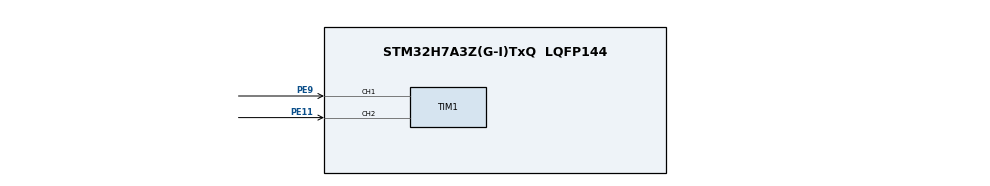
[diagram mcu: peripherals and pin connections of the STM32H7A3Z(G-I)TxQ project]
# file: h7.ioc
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Mcu.Family=STM32H7
Mcu.Name=STM32H7A3Z(G-I)TxQ
Mcu.Package=LQFP144
NVIC.PriorityGroup=NVIC_PRIORITYGROUP_4
PE11.Signal=S_TIM1_CH2
PE9.Signal=S_TIM1_CH1
PH0-OSC_IN.Mode=HSE-External-Oscillator
PH0-OSC_IN.Signal=RCC_OSC_IN
PH1-OSC_OUT.Mode=HSE-External-Oscillator
PH1-OSC_OUT.Signal=RCC_OSC_OUT
ProjectManager.HeapSize=0x200
ProjectManager.StackSize=0x400
ProjectManager.TargetToolchain=STM32CubeIDE
RCC.ADCFreq_Value=129000000
RCC.APB1Freq_Value=32000000
RCC.APB2Freq_Value=32000000
RCC.APB3Freq_Value=32000000
RCC.APB4Freq_Value=32000000
RCC.CDPPRE=RCC_APB3_DIV2
RCC.CDPPRE1=RCC_APB1_DIV2
RCC.CDPPRE2=RCC_APB2_DIV2
RCC.CortexFreq_Value=64000000
RCC.HCLKFreq_Value=64000000
RCC.SRDPPRE=RCC_APB4_DIV2
RCC.SYSCLKFreq_VALUE=64000000
RCC.USBFreq_Value=129000000
SH.S_TIM1_CH1.0=TIM1_CH1,Encoder_Interface
SH.S_TIM1_CH2.0=TIM1_CH2,Encoder_Interface
TIM1.EncoderMode=TIM_ENCODERMODE_TI12
board=custom

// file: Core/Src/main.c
/* USER CODE BEGIN Header */
/**
  ******************************************************************************
  * @file           : main.c
  * @brief          : Main program body
  ******************************************************************************
  * @attention
  *
  * Copyright (c) 2023 STMicroelectronics.
  * All rights reserved.
  *
  * This software is licensed under terms that can be found in the LICENSE file
  * in the root directory of this software component.
  * If no LICENSE file comes with this software, it is provided AS-IS.
  *
  ******************************************************************************
  */
/* USER CODE END Header */
#include "main.h"

TIM_HandleTypeDef htim1;

/* USER CODE BEGIN PV */
int count=0;

/* USER CODE END PV */

void SystemClock_Config(void);
static void MPU_Config(void);
static void MX_GPIO_Init(void);
static void MX_TIM1_Init(void);
/* USER CODE BEGIN 0 */
void HAL_TIM_IC_CaptureCallback(TIM_HandleTypeDef *htim)
{
	count=TIM1->CNT;
	  }
/* USER CODE END 0 */

int main(void)
{

  /* MPU Configuration--------------------------------------------------------*/
  MPU_Config();

  /* MCU Configuration--------------------------------------------------------*/

  /* Reset of all peripherals, Initializes the Flash interface and the Systick. */
  HAL_Init();

  /* Configure the system clock */
  SystemClock_Config();

  /* Initialize all configured peripherals */
  MX_GPIO_Init();
  MX_TIM1_Init();
  /* USER CODE BEGIN 2 */
HAL_TIM_Encoder_Start_IT(&htim1, TIM_CHANNEL_ALL);
  /* USER CODE END 2 */

  /* Infinite loop */
  while (1)
  {

  }
}

void SystemClock_Config(void)
{
  RCC_OscInitTypeDef RCC_OscInitStruct = {0};
  RCC_ClkInitTypeDef RCC_ClkInitStruct = {0};

  /*AXI clock gating */
  RCC->CKGAENR = 0xFFFFFFFF;

  /** Supply configuration update enable
  */
  HAL_PWREx_ConfigSupply(PWR_DIRECT_SMPS_SUPPLY);

  /** Configure the main internal regulator output voltage
  */
  __HAL_PWR_VOLTAGESCALING_CONFIG(PWR_REGULATOR_VOLTAGE_SCALE3);

  while(!__HAL_PWR_GET_FLAG(PWR_FLAG_VOSRDY)) {}

  /** Initializes the RCC Oscillators according to the specified parameters
  * in the RCC_OscInitTypeDef structure.
  */
  RCC_OscInitStruct.OscillatorType = RCC_OSCILLATORTYPE_HSI;
  RCC_OscInitStruct.HSIState = RCC_HSI_DIV1;
  RCC_OscInitStruct.HSICalibrationValue = 64;
  RCC_OscInitStruct.PLL.PLLState = RCC_PLL_NONE;
  if (HAL_RCC_OscConfig(&RCC_OscInitStruct) != HAL_OK)
  {
    Error_Handler();
  }

  /** Initializes the CPU, AHB and APB buses clocks
  */
  RCC_ClkInitStruct.ClockType = RCC_CLOCKTYPE_HCLK|RCC_CLOCKTYPE_SYSCLK
                              |RCC_CLOCKTYPE_PCLK1|RCC_CLOCKTYPE_PCLK2
                              |RCC_CLOCKTYPE_D3PCLK1|RCC_CLOCKTYPE_D1PCLK1;
  RCC_ClkInitStruct.SYSCLKSource = RCC_SYSCLKSOURCE_HSI;
  RCC_ClkInitStruct.SYSCLKDivider = RCC_SYSCLK_DIV1;
  RCC_ClkInitStruct.AHBCLKDivider = RCC_HCLK_DIV1;
  RCC_ClkInitStruct.APB3CLKDivider = RCC_APB3_DIV2;
  RCC_ClkInitStruct.APB1CLKDivider = RCC_APB1_DIV2;
  RCC_ClkInitStruct.APB2CLKDivider = RCC_APB2_DIV2;
  RCC_ClkInitStruct.APB4CLKDivider = RCC_APB4_DIV2;

  if (HAL_RCC_ClockConfig(&RCC_ClkInitStruct, FLASH_LATENCY_2) != HAL_OK)
  {
    Error_Handler();
  }
}

static void MX_TIM1_Init(void)
{

  TIM_Encoder_InitTypeDef sConfig = {0};
  TIM_MasterConfigTypeDef sMasterConfig = {0};

  htim1.Instance = TIM1;
  htim1.Init.Prescaler = 0;
  htim1.Init.CounterMode = TIM_COUNTERMODE_UP;
  htim1.Init.Period = 65535;
  htim1.Init.ClockDivision = TIM_CLOCKDIVISION_DIV1;
  htim1.Init.RepetitionCounter = 0;
  htim1.Init.AutoReloadPreload = TIM_AUTORELOAD_PRELOAD_DISABLE;
  sConfig.EncoderMode = TIM_ENCODERMODE_TI12;
  sConfig.IC1Polarity = TIM_ICPOLARITY_RISING;
  sConfig.IC1Selection = TIM_ICSELECTION_DIRECTTI;
  sConfig.IC1Prescaler = TIM_ICPSC_DIV1;
  sConfig.IC1Filter = 0;
  sConfig.IC2Polarity = TIM_ICPOLARITY_RISING;
  sConfig.IC2Selection = TIM_ICSELECTION_DIRECTTI;
  sConfig.IC2Prescaler = TIM_ICPSC_DIV1;
  sConfig.IC2Filter = 0;
  if (HAL_TIM_Encoder_Init(&htim1, &sConfig) != HAL_OK)
  {
    Error_Handler();
  }
  sMasterConfig.MasterOutputTrigger = TIM_TRGO_RESET;
  sMasterConfig.MasterOutputTrigger2 = TIM_TRGO2_RESET;
  sMasterConfig.MasterSlaveMode = TIM_MASTERSLAVEMODE_DISABLE;
  if (HAL_TIMEx_MasterConfigSynchronization(&htim1, &sMasterConfig) != HAL_OK)
  {
    Error_Handler();
  }

}

static void MX_GPIO_Init(void)
{

  /* GPIO Ports Clock Enable */
  __HAL_RCC_GPIOH_CLK_ENABLE();
  __HAL_RCC_GPIOE_CLK_ENABLE();

}

/* MPU Configuration */

void MPU_Config(void)
{
  MPU_Region_InitTypeDef MPU_InitStruct = {0};

  /* Disables the MPU */
  HAL_MPU_Disable();

  /** Initializes and configures the Region and the memory to be protected
  */
  MPU_InitStruct.Enable = MPU_REGION_ENABLE;
  MPU_InitStruct.Number = MPU_REGION_NUMBER0;
  MPU_InitStruct.BaseAddress = 0x0;
  MPU_InitStruct.Size = MPU_REGION_SIZE_4GB;
  MPU_InitStruct.SubRegionDisable = 0x87;
  MPU_InitStruct.TypeExtField = MPU_TEX_LEVEL0;
  MPU_InitStruct.AccessPermission = MPU_REGION_NO_ACCESS;
  MPU_InitStruct.DisableExec = MPU_INSTRUCTION_ACCESS_DISABLE;
  MPU_InitStruct.IsShareable = MPU_ACCESS_SHAREABLE;
  MPU_InitStruct.IsCacheable = MPU_ACCESS_NOT_CACHEABLE;
  MPU_InitStruct.IsBufferable = MPU_ACCESS_NOT_BUFFERABLE;

  HAL_MPU_ConfigRegion(&MPU_InitStruct);
  /* Enables the MPU */
  HAL_MPU_Enable(MPU_PRIVILEGED_DEFAULT);

}

void Error_Handler(void)
{
  __disable_irq();
  while (1)
  {
  }
}
